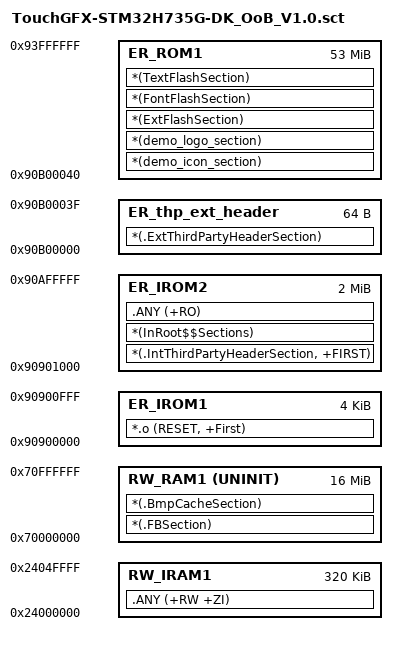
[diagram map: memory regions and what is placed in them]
; *************************************************************
; *** Scatter-Loading Description File generated by uVision ***
; *************************************************************

LR_IROM1 0x90900000 0x1000  {    ; load region size_region
  ER_IROM1 0x90900000 0x1000  {  ; load address = execution address
   *.o (RESET, +First)
    }
}
LR_IROM2 0x90901000 0x1FF000  {    ; load region size_region
  ER_IROM2 0x90901000 0x1FF000  { ; load address = execution address
   *(.IntThirdPartyHeaderSection, +FIRST)
   *(InRoot$$Sections)
   .ANY (+RO)
   }
  RW_RAM1 0x70000000 UNINIT 0x01000000  {  ; RW data
   *(.FBSection)
   *(.BmpCacheSection)
  }
  RW_IRAM1 0x24000000 0x00050000  {
  .ANY (+RW +ZI)
  }
}

LR_ROM1 0x90B00000 0x3500000  {
  ER_thp_ext_header 0x90B00000  0x40  {  ; load address = execution address
  *(.ExtThirdPartyHeaderSection)
  }
  ER_ROM1 0x90B00040 0x34FFFC0 {
	*(demo_icon_section)
	*(demo_logo_section)
	*(ExtFlashSection)
	*(FontFlashSection)	
	*(TextFlashSection)
  }
 
}
